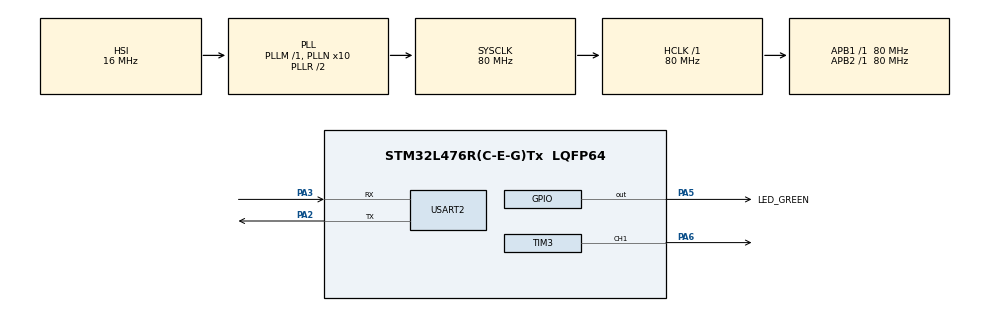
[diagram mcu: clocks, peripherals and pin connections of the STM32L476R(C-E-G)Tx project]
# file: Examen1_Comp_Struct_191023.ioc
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Dma.Request0=USART2_TX
Dma.USART2_TX.0.Direction=DMA_MEMORY_TO_PERIPH
Dma.USART2_TX.0.Instance=DMA1_Channel7
Dma.USART2_TX.0.MemDataAlignment=DMA_MDATAALIGN_BYTE
Dma.USART2_TX.0.MemInc=DMA_MINC_ENABLE
Dma.USART2_TX.0.Mode=DMA_NORMAL
Dma.USART2_TX.0.PeriphDataAlignment=DMA_PDATAALIGN_BYTE
Dma.USART2_TX.0.PeriphInc=DMA_PINC_DISABLE
Dma.USART2_TX.0.Priority=DMA_PRIORITY_LOW
Mcu.Family=STM32L4
Mcu.Name=STM32L476R(C-E-G)Tx
Mcu.Package=LQFP64
NVIC.DMA1_Channel7_IRQn=true\:0\:0\:false\:false\:true\:false\:true\:true
NVIC.PriorityGroup=NVIC_PRIORITYGROUP_4
NVIC.USART2_IRQn=true\:0\:0\:false\:false\:true\:true\:true\:true
PA2.Mode=Asynchronous
PA2.Signal=USART2_TX
PA3.Mode=Asynchronous
PA3.Signal=USART2_RX
PA5.GPIO_Label=LED_GREEN
PA5.Signal=GPIO_Output
PA6.Signal=S_TIM3_CH1
ProjectManager.HeapSize=0x200
ProjectManager.StackSize=0x400
ProjectManager.TargetToolchain=STM32CubeIDE
RCC.ADCFreq_Value=64000000
RCC.AHBFreq_Value=80000000
RCC.APB1Freq_Value=80000000
RCC.APB1TimFreq_Value=80000000
RCC.APB2Freq_Value=80000000
RCC.APB2TimFreq_Value=80000000
RCC.CortexFreq_Value=80000000
RCC.HCLKFreq_Value=80000000
RCC.HSE_VALUE=8000000
RCC.HSI_VALUE=16000000
RCC.LSE_VALUE=32768
RCC.MSI_VALUE=4000000
RCC.PLLN=10
RCC.PLLSourceVirtual=RCC_PLLSOURCE_HSI
RCC.PREFETCH_ENABLE=1
RCC.SYSCLKFreq_VALUE=80000000
RCC.SYSCLKSource=RCC_SYSCLKSOURCE_PLLCLK
RCC.USBFreq_Value=64000000
RCC.VCOOutputFreq_Value=160000000
SH.S_TIM3_CH1.0=TIM3_CH1,PWM Generation1 CH1
TIM3.Channel-PWM\ Generation1\ CH1=TIM_CHANNEL_1
USART2.VirtualMode-Asynchronous=VM_ASYNC
VP_TIM16_VS_ClockSourceINT.Mode=Enable_Timer
VP_TIM3_VS_ClockSourceINT.Mode=Internal
board=NUCLEO-L476RG

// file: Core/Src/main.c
/* USER CODE BEGIN Header */
/**
  ******************************************************************************
  * @file           : main.c
  * @brief          : Main program body
  ******************************************************************************
  * @attention
  *
  * Copyright (c) 2023 STMicroelectronics.
  * All rights reserved.
  *
  * This software is licensed under terms that can be found in the LICENSE file
  * in the root directory of this software component.
  * If no LICENSE file comes with this software, it is provided AS-IS.
  *
  ******************************************************************************
  */
/* USER CODE END Header */
#include "main.h"
#include "stdio.h"

TIM_HandleTypeDef htim3;
TIM_HandleTypeDef htim16;

UART_HandleTypeDef huart2;
DMA_HandleTypeDef hdma_usart2_tx;

/* USER CODE BEGIN PV */

// Definimos las variables de nuestro ciclo útil

uint16_t duty = 0; // Variable para almacenar el valor del PWM
uint16_t maxDuty = 0; // Variable para controlar el máximo del ciclo útil
uint8_t rx_buffer[4];

/* USER CODE END PV */

void SystemClock_Config(void);
static void MX_GPIO_Init(void);
static void MX_DMA_Init(void);
static void MX_USART2_UART_Init(void);
static void MX_TIM3_Init(void);
static void MX_TIM16_Init(void);

int main(void)
{

  /* MCU Configuration--------------------------------------------------------*/

  /* Reset of all peripherals, Initializes the Flash interface and the Systick. */
  HAL_Init();

  /* Configure the system clock */
  SystemClock_Config();

  /* Initialize all configured peripherals */
  MX_GPIO_Init();
  MX_DMA_Init();
  MX_USART2_UART_Init();
  MX_TIM3_Init();
  MX_TIM16_Init();
  /* USER CODE BEGIN 2 */

  // Iniciamos el contador del Timer 16 en modo Interrupción
  HAL_TIM_Base_Start_IT(&htim16);

  // Iniciamos el PWM en el Timmer 2 en el canal 1
  HAL_TIM_PWM_Start(&htim3, TIM_CHANNEL_1);

  // Definimos la variable maxDuty igual al registro ARR
  maxDuty = htim3.Instance->ARR;

  HAL_UART_Receive_IT(&huart2, rx_buffer, 1);

  /* USER CODE END 2 */

  /* Infinite loop */
  /* USER CODE BEGIN WHILE */
  while (1)
  {
	  // Aumentamos el Duty hasta llegar al máximo valor
	  for (duty = 0; duty < maxDuty; ++duty) {
		  htim3.Instance->CCR1 = duty; // El ancho del  pulso del canal 0 (PA6) va a ir incrementando hasta llegar al ARR
		  // Imprimir el valor del PWM cada 1 segundo
		  HAL_Delay(1000);
		  printf("PWM Value: %d\r\n", duty);

		  HAL_Delay(1);
	  }

    /* USER CODE END WHILE */

  }
}

void SystemClock_Config(void)
{
  RCC_OscInitTypeDef RCC_OscInitStruct = {0};
  RCC_ClkInitTypeDef RCC_ClkInitStruct = {0};

  /** Configure the main internal regulator output voltage
  */
  if (HAL_PWREx_ControlVoltageScaling(PWR_REGULATOR_VOLTAGE_SCALE1) != HAL_OK)
  {
    Error_Handler();
  }

  /** Initializes the RCC Oscillators according to the specified parameters
  * in the RCC_OscInitTypeDef structure.
  */
  RCC_OscInitStruct.OscillatorType = RCC_OSCILLATORTYPE_HSI;
  RCC_OscInitStruct.HSIState = RCC_HSI_ON;
  RCC_OscInitStruct.HSICalibrationValue = RCC_HSICALIBRATION_DEFAULT;
  RCC_OscInitStruct.PLL.PLLState = RCC_PLL_ON;
  RCC_OscInitStruct.PLL.PLLSource = RCC_PLLSOURCE_HSI;
  RCC_OscInitStruct.PLL.PLLM = 1;
  RCC_OscInitStruct.PLL.PLLN = 10;
  RCC_OscInitStruct.PLL.PLLP = RCC_PLLP_DIV7;
  RCC_OscInitStruct.PLL.PLLQ = RCC_PLLQ_DIV2;
  RCC_OscInitStruct.PLL.PLLR = RCC_PLLR_DIV2;
  if (HAL_RCC_OscConfig(&RCC_OscInitStruct) != HAL_OK)
  {
    Error_Handler();
  }

  /** Initializes the CPU, AHB and APB buses clocks
  */
  RCC_ClkInitStruct.ClockType = RCC_CLOCKTYPE_HCLK|RCC_CLOCKTYPE_SYSCLK
                              |RCC_CLOCKTYPE_PCLK1|RCC_CLOCKTYPE_PCLK2;
  RCC_ClkInitStruct.SYSCLKSource = RCC_SYSCLKSOURCE_PLLCLK;
  RCC_ClkInitStruct.AHBCLKDivider = RCC_SYSCLK_DIV1;
  RCC_ClkInitStruct.APB1CLKDivider = RCC_HCLK_DIV1;
  RCC_ClkInitStruct.APB2CLKDivider = RCC_HCLK_DIV1;

  if (HAL_RCC_ClockConfig(&RCC_ClkInitStruct, FLASH_LATENCY_4) != HAL_OK)
  {
    Error_Handler();
  }
}

static void MX_TIM3_Init(void)
{

  TIM_ClockConfigTypeDef sClockSourceConfig = {0};
  TIM_MasterConfigTypeDef sMasterConfig = {0};
  TIM_OC_InitTypeDef sConfigOC = {0};

  htim3.Instance = TIM3;
  htim3.Init.Prescaler = 0;
  htim3.Init.CounterMode = TIM_COUNTERMODE_UP;
  htim3.Init.Period = 65535;
  htim3.Init.ClockDivision = TIM_CLOCKDIVISION_DIV1;
  htim3.Init.AutoReloadPreload = TIM_AUTORELOAD_PRELOAD_DISABLE;
  if (HAL_TIM_Base_Init(&htim3) != HAL_OK)
  {
    Error_Handler();
  }
  sClockSourceConfig.ClockSource = TIM_CLOCKSOURCE_INTERNAL;
  if (HAL_TIM_ConfigClockSource(&htim3, &sClockSourceConfig) != HAL_OK)
  {
    Error_Handler();
  }
  if (HAL_TIM_PWM_Init(&htim3) != HAL_OK)
  {
    Error_Handler();
  }
  sMasterConfig.MasterOutputTrigger = TIM_TRGO_RESET;
  sMasterConfig.MasterSlaveMode = TIM_MASTERSLAVEMODE_DISABLE;
  if (HAL_TIMEx_MasterConfigSynchronization(&htim3, &sMasterConfig) != HAL_OK)
  {
    Error_Handler();
  }
  sConfigOC.OCMode = TIM_OCMODE_PWM1;
  sConfigOC.Pulse = 0;
  sConfigOC.OCPolarity = TIM_OCPOLARITY_HIGH;
  sConfigOC.OCFastMode = TIM_OCFAST_DISABLE;
  if (HAL_TIM_PWM_ConfigChannel(&htim3, &sConfigOC, TIM_CHANNEL_1) != HAL_OK)
  {
    Error_Handler();
  }
  HAL_TIM_MspPostInit(&htim3);

}

static void MX_TIM16_Init(void)
{

  htim16.Instance = TIM16;
  htim16.Init.Prescaler = 0;
  htim16.Init.CounterMode = TIM_COUNTERMODE_UP;
  htim16.Init.Period = 65535;
  htim16.Init.ClockDivision = TIM_CLOCKDIVISION_DIV1;
  htim16.Init.RepetitionCounter = 0;
  htim16.Init.AutoReloadPreload = TIM_AUTORELOAD_PRELOAD_DISABLE;
  if (HAL_TIM_Base_Init(&htim16) != HAL_OK)
  {
    Error_Handler();
  }

}

static void MX_USART2_UART_Init(void)
{

  huart2.Instance = USART2;
  huart2.Init.BaudRate = 115200;
  huart2.Init.WordLength = UART_WORDLENGTH_8B;
  huart2.Init.StopBits = UART_STOPBITS_1;
  huart2.Init.Parity = UART_PARITY_NONE;
  huart2.Init.Mode = UART_MODE_TX_RX;
  huart2.Init.HwFlowCtl = UART_HWCONTROL_NONE;
  huart2.Init.OverSampling = UART_OVERSAMPLING_16;
  huart2.Init.OneBitSampling = UART_ONE_BIT_SAMPLE_DISABLE;
  huart2.AdvancedInit.AdvFeatureInit = UART_ADVFEATURE_NO_INIT;
  if (HAL_UART_Init(&huart2) != HAL_OK)
  {
    Error_Handler();
  }

}

static void MX_DMA_Init(void)
{

  /* DMA controller clock enable */
  __HAL_RCC_DMA1_CLK_ENABLE();

  /* DMA interrupt init */
  /* DMA1_Channel7_IRQn interrupt configuration */
  HAL_NVIC_SetPriority(DMA1_Channel7_IRQn, 0, 0);
  HAL_NVIC_EnableIRQ(DMA1_Channel7_IRQn);

}

static void MX_GPIO_Init(void)
{
  GPIO_InitTypeDef GPIO_InitStruct = {0};

  /* GPIO Ports Clock Enable */
  __HAL_RCC_GPIOA_CLK_ENABLE();

  /*Configure GPIO pin Output Level */
  HAL_GPIO_WritePin(LED_GREEN_GPIO_Port, LED_GREEN_Pin, GPIO_PIN_RESET);

  /*Configure GPIO pin : LED_GREEN_Pin */
  GPIO_InitStruct.Pin = LED_GREEN_Pin;
  GPIO_InitStruct.Mode = GPIO_MODE_OUTPUT_PP;
  GPIO_InitStruct.Pull = GPIO_NOPULL;
  GPIO_InitStruct.Speed = GPIO_SPEED_FREQ_LOW;
  HAL_GPIO_Init(LED_GREEN_GPIO_Port, &GPIO_InitStruct);

}

void Error_Handler(void)
{
  __disable_irq();
  while (1)
  {
  }
}
